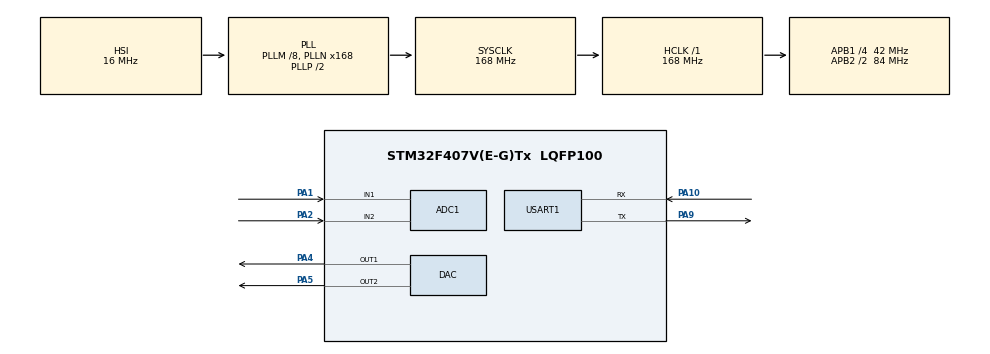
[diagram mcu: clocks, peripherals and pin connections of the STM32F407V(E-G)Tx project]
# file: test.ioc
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ADC1.Channel-0\#ChannelRegularConversion=ADC_CHANNEL_2
ADC1.Channel-3\#ChannelRegularConversion=ADC_CHANNEL_1
ADC1.ContinuousConvMode=ENABLE
ADC1.DMAContinuousRequests=ENABLE
ADC1.DiscontinuousConvMode=DISABLE
ADC1.NbrOfConversion=2
ADC1.NbrOfConversionFlag=1
ADC1.Rank-0\#ChannelRegularConversion=1
ADC1.Rank-3\#ChannelRegularConversion=2
ADC1.SamplingTime-0\#ChannelRegularConversion=ADC_SAMPLETIME_144CYCLES
ADC1.SamplingTime-3\#ChannelRegularConversion=ADC_SAMPLETIME_144CYCLES
ADC1.ScanConvMode=ENABLE
ADC1.master=1
Dma.ADC1.0.Direction=DMA_PERIPH_TO_MEMORY
Dma.ADC1.0.FIFOMode=DMA_FIFOMODE_DISABLE
Dma.ADC1.0.Instance=DMA2_Stream0
Dma.ADC1.0.MemDataAlignment=DMA_MDATAALIGN_HALFWORD
Dma.ADC1.0.MemInc=DMA_MINC_ENABLE
Dma.ADC1.0.Mode=DMA_CIRCULAR
Dma.ADC1.0.PeriphDataAlignment=DMA_PDATAALIGN_HALFWORD
Dma.ADC1.0.PeriphInc=DMA_PINC_DISABLE
Dma.ADC1.0.Priority=DMA_PRIORITY_LOW
Dma.Request0=ADC1
Mcu.Family=STM32F4
Mcu.Name=STM32F407V(E-G)Tx
Mcu.Package=LQFP100
NVIC.DMA2_Stream0_IRQn=true\:0\:0\:false\:false\:true\:false\:true\:true
NVIC.PriorityGroup=NVIC_PRIORITYGROUP_4
NVIC.TIM2_IRQn=true\:0\:0\:false\:false\:true\:true\:true\:true
NVIC.USART1_IRQn=true\:0\:0\:false\:false\:true\:true\:true\:true
PA1.Signal=ADCx_IN1
PA10.Mode=Asynchronous
PA10.Signal=USART1_RX
PA13.Mode=Serial_Wire
PA13.Signal=SYS_JTMS-SWDIO
PA14.Mode=Serial_Wire
PA14.Signal=SYS_JTCK-SWCLK
PA2.Signal=ADCx_IN2
PA4.Signal=COMP_DAC1_group
PA5.Signal=COMP_DAC2_group
PA9.Mode=Asynchronous
PA9.Signal=USART1_TX
PH0-OSC_IN.Mode=HSE-External-Oscillator
PH0-OSC_IN.Signal=RCC_OSC_IN
PH1-OSC_OUT.Mode=HSE-External-Oscillator
PH1-OSC_OUT.Signal=RCC_OSC_OUT
ProjectManager.HeapSize=0x200
ProjectManager.StackSize=0x400
ProjectManager.TargetToolchain=STM32CubeIDE
RCC.48MHZClocksFreq_Value=84000000
RCC.AHBFreq_Value=168000000
RCC.APB1CLKDivider=RCC_HCLK_DIV4
RCC.APB1Freq_Value=42000000
RCC.APB1TimFreq_Value=84000000
RCC.APB2CLKDivider=RCC_HCLK_DIV2
RCC.APB2Freq_Value=84000000
RCC.APB2TimFreq_Value=168000000
RCC.CortexFreq_Value=168000000
RCC.HCLKFreq_Value=168000000
RCC.HSE_VALUE=25000000
RCC.HSI_VALUE=16000000
RCC.LSE_VALUE=32768
RCC.PLLM=8
RCC.PLLN=168
RCC.SYSCLKFreq_VALUE=168000000
RCC.SYSCLKSource=RCC_SYSCLKSOURCE_PLLCLK
RCC.VCOOutputFreq_Value=336000000
SH.ADCx_IN1.0=ADC1_IN1,IN1
SH.ADCx_IN2.0=ADC1_IN2,IN2
SH.COMP_DAC1_group.0=DAC_OUT1,DAC_OUT1
SH.COMP_DAC2_group.0=DAC_OUT2,DAC_OUT2
TIM2.AutoReloadPreload=TIM_AUTORELOAD_PRELOAD_ENABLE
TIM2.Period=9999
TIM2.Prescaler=8399
USART1.VirtualMode=VM_ASYNC
VP_TIM2_VS_ClockSourceINT.Mode=Internal
board=custom

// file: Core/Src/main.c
/* USER CODE BEGIN Header */
/**
  ******************************************************************************
  * @file           : main.c
  * @brief          : Main program body
  ******************************************************************************
  * @attention
  *
  * Copyright (c) 2023 STMicroelectronics.
  * All rights reserved.
  *
  * This software is licensed under terms that can be found in the LICENSE file
  * in the root directory of this software component.
  * If no LICENSE file comes with this software, it is provided AS-IS.
  *
  ******************************************************************************
  */
/* USER CODE END Header */
#include "main.h"
#include "adc.h"
#include "dac.h"
#include "dma.h"
#include "tim.h"
#include "usart.h"
#include "gpio.h"

/* USER CODE BEGIN Includes */
#include<stdio.h>
uint16_t AD_Value[16]={0};
/* USER CODE END Includes */

/* USER CODE BEGIN PTD */

int _write(int fd, char *ptr, int len)
{
  HAL_UART_Transmit(&huart1, (uint8_t*)ptr, len, 0xFFFF);
  return len;
}
/* USER CODE END PTD */

void SystemClock_Config(void);

int main(void)
{

  /* MCU Configuration--------------------------------------------------------*/

  /* Reset of all peripherals, Initializes the Flash interface and the Systick. */
  HAL_Init();

  /* Configure the system clock */
  SystemClock_Config();

  /* Initialize all configured peripherals */
  MX_GPIO_Init();
  MX_DMA_Init();
  MX_USART1_UART_Init();
  MX_TIM2_Init();
  MX_ADC1_Init();
  MX_DAC_Init();
  /* USER CODE BEGIN 2 */

  HAL_DAC_SetValue(&hdac, DAC_CHANNEL_1, DAC_ALIGN_12B_R, 1024);
  HAL_DAC_Start(&hdac,DAC_CHANNEL_1);

  HAL_DAC_SetValue(&hdac, DAC_CHANNEL_2, DAC_ALIGN_12B_R, 2048);
  HAL_DAC_Start(&hdac,DAC_CHANNEL_2);

  HAL_ADC_Start_DMA(&hadc1,(uint32_t*)&AD_Value,16);

  // 清除定时器初始化过程中的更新中断标志，避免定时器�??????启动就中�??????
  __HAL_TIM_CLEAR_IT(&htim2, TIM_IT_UPDATE);
  // 使能定时�??????3更新中断并启动定时器
  HAL_TIM_Base_Start_IT(&htim2);
  /* USER CODE END 2 */

  /* Infinite loop */
  while (1)
  {

    /* USER CODE BEGIN 3 */
//	printf("while采集成功\r\n");
// 	printf("ADC0:%d\r\n",AD_Value[0]);
//	printf("ADC1:%d\r\n",AD_Value[1]);
//	printf("\r\n");
//	HAL_Delay(1500);

  }
  /* USER CODE END 3 */
}

void SystemClock_Config(void)
{
  RCC_OscInitTypeDef RCC_OscInitStruct = {0};
  RCC_ClkInitTypeDef RCC_ClkInitStruct = {0};

  /** Configure the main internal regulator output voltage
  */
  __HAL_RCC_PWR_CLK_ENABLE();
  __HAL_PWR_VOLTAGESCALING_CONFIG(PWR_REGULATOR_VOLTAGE_SCALE1);

  /** Initializes the RCC Oscillators according to the specified parameters
  * in the RCC_OscInitTypeDef structure.
  */
  RCC_OscInitStruct.OscillatorType = RCC_OSCILLATORTYPE_HSI;
  RCC_OscInitStruct.HSIState = RCC_HSI_ON;
  RCC_OscInitStruct.HSICalibrationValue = RCC_HSICALIBRATION_DEFAULT;
  RCC_OscInitStruct.PLL.PLLState = RCC_PLL_ON;
  RCC_OscInitStruct.PLL.PLLSource = RCC_PLLSOURCE_HSI;
  RCC_OscInitStruct.PLL.PLLM = 8;
  RCC_OscInitStruct.PLL.PLLN = 168;
  RCC_OscInitStruct.PLL.PLLP = RCC_PLLP_DIV2;
  RCC_OscInitStruct.PLL.PLLQ = 4;
  if (HAL_RCC_OscConfig(&RCC_OscInitStruct) != HAL_OK)
  {
    Error_Handler();
  }

  /** Initializes the CPU, AHB and APB buses clocks
  */
  RCC_ClkInitStruct.ClockType = RCC_CLOCKTYPE_HCLK|RCC_CLOCKTYPE_SYSCLK
                              |RCC_CLOCKTYPE_PCLK1|RCC_CLOCKTYPE_PCLK2;
  RCC_ClkInitStruct.SYSCLKSource = RCC_SYSCLKSOURCE_PLLCLK;
  RCC_ClkInitStruct.AHBCLKDivider = RCC_SYSCLK_DIV1;
  RCC_ClkInitStruct.APB1CLKDivider = RCC_HCLK_DIV4;
  RCC_ClkInitStruct.APB2CLKDivider = RCC_HCLK_DIV2;

  if (HAL_RCC_ClockConfig(&RCC_ClkInitStruct, FLASH_LATENCY_5) != HAL_OK)
  {
    Error_Handler();
  }
}

void Error_Handler(void)
{
  __disable_irq();
  while (1)
  {
  }
}
